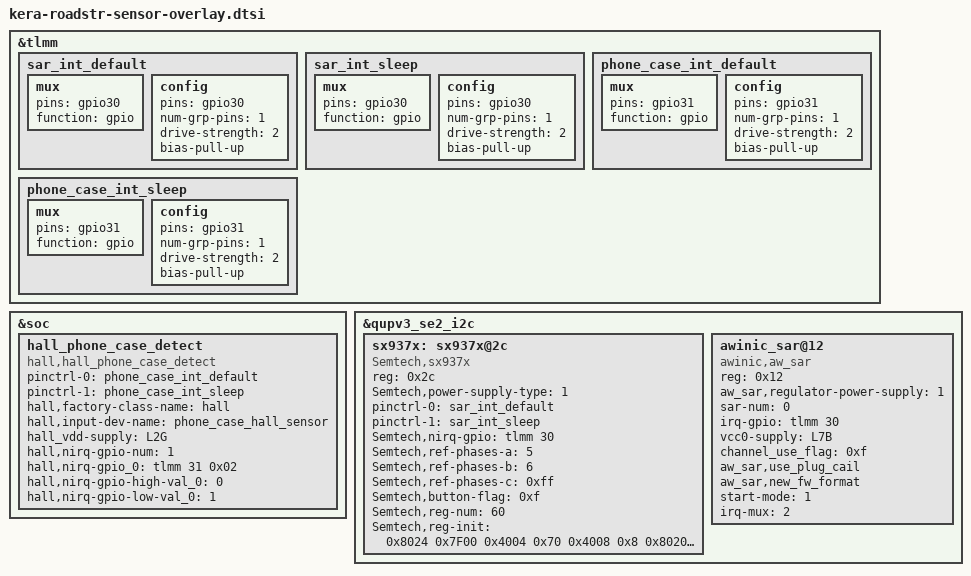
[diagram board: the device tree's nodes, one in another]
/* Copyright (c) 2021, The Linux Foundation. All rights reserved.
 *
 * This program is free software; you can redistribute it and/or modify
 * it under the terms of the GNU General Public License version 2 and
 * only version 2 as published by the Free Software Foundation.
 *
 * This program is distributed in the hope that it will be useful,
 * but WITHOUT ANY WARRANTY; without even the implied warranty of
 * MERCHANTABILITY or FITNESS FOR A PARTICULAR PURPOSE.  See the
 * GNU General Public License for more details.
 */

&tlmm {
        sar_int_default: sar_int_default {
                        mux {
                                pins = "gpio30";
                                function =  "gpio";
                        };
                        config {
                                pins = "gpio30";
                                num-grp-pins = <1>;
                                drive-strength = <2>;
                                bias-pull-up;
                        };
        };
        sar_int_sleep: sar_int_sleep {
                        mux {
                                pins = "gpio30";
                                function =  "gpio";
                        };
                        config {
                                pins = "gpio30";
                                num-grp-pins = <1>;
                                drive-strength = <2>;
                                bias-pull-up;
                        };
        };

        phone_case_int_default: phone_case_int_default {
			mux {
				pins = "gpio31";
				function =  "gpio";
			};
			config {
				pins = "gpio31";
				num-grp-pins = <1>;
				drive-strength = <2>;
				bias-pull-up;
			};
	};

	phone_case_int_sleep: phone_case_int_sleep {
			mux {
				pins = "gpio31";
				function =  "gpio";
			};
			config {
				pins = "gpio31";
				num-grp-pins = <1>;
				drive-strength = <2>;
				bias-pull-up;
			};
	};
};


&soc {
	hall_phone_case_detect {
		compatible = "hall,hall_phone_case_detect";
		pinctrl-names = "default","sleep";
		pinctrl-0 = <&phone_case_int_default>;
		pinctrl-1 = <&phone_case_int_sleep>;
		hall,factory-class-name = "hall";
		hall,input-dev-name = "phone_case_hall_sensor";
		hall_vdd-supply = <&L2G>;
		hall,nirq-gpio-num = <1>;
		hall,nirq-gpio_0 = <&tlmm 31 0x02>;
		hall,nirq-gpio-high-val_0 = <0>;
		hall,nirq-gpio-low-val_0 = <1>;
	};
};

&qupv3_se2_i2c {
        status = "ok";
        sx937x:sx937x@2c {
                compatible = "Semtech,sx937x";
                reg = <0x2c>;
                Semtech,power-supply-type = <1>;
                //cap_vdd-supply = <&L7B>;
                pinctrl-names = "default","sleep";
                pinctrl-0 = <&sar_int_default>;
                pinctrl-1 = <&sar_int_sleep>;
                //interrupt-parent = <&tlmm>;
                //interrupts = <30 0x02>;
                //interrupt-names = "sx937x_irq";
                Semtech,nirq-gpio = <&tlmm 30 0x02>;
                //esd-reinit-on = <1>;
                /*use PH5/6 as the reference sensor
                set it to 0xff if the ref-phases-x is not used*/
                Semtech,ref-phases-a = <5>;
                Semtech,ref-phases-b = <6>;
                Semtech,ref-phases-c = <0xff>;
                Semtech,button-flag = <0xf>;
                Semtech,reg-num = <60>;
                Semtech,reg-init = <
                          0x8024  0x7F00
                          0x4004  0x70
                          0x4008  0x8
                          0x8020  0x32
                          0x8028  0xD5E
                          0x8034  0xD5E
                          0x8040  0xD5E
                          0x804C  0xD5E
                          0x8058  0xD5E
                          0x8064  0xD5E
                          0x8070  0xD5E
                          0x807C  0x85E
                          0x8030  0x924925
                          0x803C  0x92C924
                          0x8048  0x964924
                          0x8054  0x924964
                          0x8060  0x92492C
                          0x806C  0x925924
                          0x8078  0xB24924
                          0x8084  0xFFF9FF
                          0x8098  0x6E4F
                          0x80B8  0x3F36
                          0x80D8  0x3636
                          0x80F8  0x6464
                          0x8118  0x5A5A
                          0x8138  0x5A40
                          0x8158  0x5A40
                          0x8178  0x5A40
                          0x80A0  0x20200001
                          0x80C0  0x10100002
                          0x80E0  0x707001A
                          0x8100  0x49490002
                          0x8188  0x8000004
                          0x818C  0x8000005
                          0x8190  0x8000006
                          0x8090  0x20005000
                          0x80B0  0x8005000
                          0x80D0  0x78885001
                          0x80F0  0x10005000
                          0x8110  0x54AC5000
                          0x8130  0x54AC5000
                          0x8150  0x54AC5000
                          0x8170  0x54AC5000
                          0x8088  0x300000
                          0x80A8  0x300000
                          0x80C8  0x300000
                          0x80E8  0x300000
                          0x8108  0x300000
                          0x8128  0x300000
                          0x8148  0x300000
                          0x8168  0x300000
                          0x808C  0x60200030
                          0x80AC  0x60200030
                          0x80CC  0x60200030
                          0x80EC  0x60200030
                          0x810C  0x60200030
                          0x812C  0x60200030
                          0x814C  0x60200030
                          0x816C  0x60200030
                          0x8274  0x2E040010
                >;
                status = "ok";
        };

};

&qupv3_se2_i2c {
        status = "okay";
        awinic_sar@12 {
                /* common node */
                compatible = "awinic,aw_sar";
                reg = < 0x12 >;
                aw_sar,regulator-power-supply = <1>;
                sar-num = < 0 >;
                //interrupt-parent = < &tlmm >;
                //interrupts = <58 0x02>;
                //interrupt-names = "awinic_irq";
                irq-gpio = <&tlmm 30 0x02>;
                vcc0-supply = <&L7B>;
                channel_use_flag = <0xf>;
                aw_sar,use_plug_cail;
                aw_sar,new_fw_format;
                //aw_sar,update_fw;
                /* private node belongs to aw963xx */
                start-mode = < 1 >; // 0: start in rom  1: start in ram
                irq-mux = < 2 >; // set csx as irq pin. config this field when connect to aw96308/aw96310
                status = "okay";
        };

};
